VERSION ""

NS_ :

BS_:

BU_:

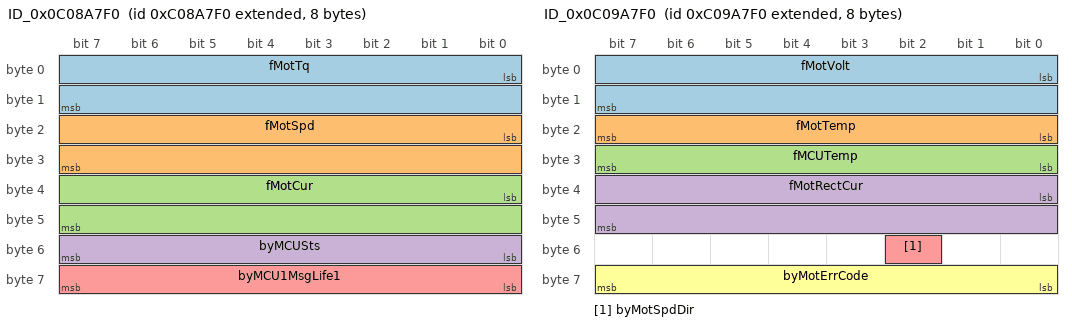
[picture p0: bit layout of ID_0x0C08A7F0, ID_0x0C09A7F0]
BO_ 2349377520 ID_0x0C08A7F0: 8 Vector__XXX
 SG_ fMotTq : 0|16@1+ (1,-32000) [-32000|33535] "NM" Vector__XXX
 SG_ fMotSpd : 16|16@1+ (0.5,0) [0|32767.5] "RPM" Vector__XXX
 SG_ fMotCur : 32|16@1+ (0.1,-1000) [-1000|5553.5] "A" Vector__XXX
 SG_ byMCUSts : 48|8@1+ (1,0) [0|255] "" Vector__XXX
 SG_ byMCU1MsgLife1 : 56|8@1+ (1,0) [0|255] "" Vector__XXX

BO_ 2349443056 ID_0x0C09A7F0: 8 Vector__XXX
 SG_ fMotVolt : 0|16@1+ (0.1,-1000) [-1000|5553.5] "V" Vector__XXX
 SG_ fMotTemp : 16|8@1+ (1,-40) [-40|215] "" Vector__XXX
 SG_ fMCUTemp : 24|8@1+ (1,-40) [-40|215] "" Vector__XXX
 SG_ fMotRectCur : 32|16@1+ (0.1,-1000) [-1000|5553.5] "A" Vector__XXX
 SG_ byMotSpdDir : 50|1@1+ (1,0) [0|1] "" Vector__XXX
 SG_ byMotErrCode : 56|8@1+ (1,0) [0|255] "" Vector__XXX

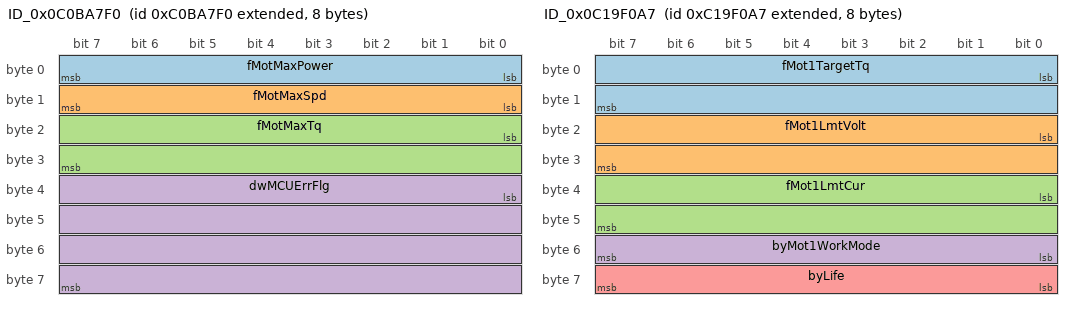
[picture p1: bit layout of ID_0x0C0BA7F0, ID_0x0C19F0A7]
BO_ 2349574128 ID_0x0C0BA7F0: 8 Vector__XXX
 SG_ fMotMaxPower : 0|8@1+ (1,0) [0|255] "kw" Vector__XXX
 SG_ fMotMaxSpd : 8|8@1+ (100,0) [0|25500] "rpm" Vector__XXX
 SG_ fMotMaxTq : 16|16@1+ (1,0) [0|65535] "NM" Vector__XXX
 SG_ dwMCUErrFlg : 32|32@1+ (1,0) [0|4294967295] "" Vector__XXX

BO_ 2350510247 ID_0x0C19F0A7: 8 Vector__XX
 SG_ fMot1TargetTq : 0|16@1+ (1,-32000) [-32000|33535] "NM" Vector__XXX
 SG_ fMot1LmtVolt : 16|16@1+ (0.1,-1000) [-1000|5553.5] "V" Vector__XXX
 SG_ fMot1LmtCur : 32|16@1+ (0.1,-1000) [-1000|5553.5] "A" Vector__XXX
 SG_ byMot1WorkMode : 48|8@1+ (1,0) [0|255] "" Vector__XXX
 SG_ byLife : 56|8@1+ (1,0) [0|255] "" Vector__XXX

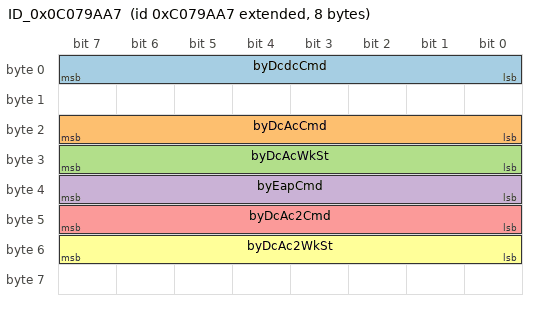
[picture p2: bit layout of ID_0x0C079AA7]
BO_ 2349308583 ID_0x0C079AA7: 8 Vector__XX
 SG_ byDcdcCmd : 0|8@1+ (1,0) [0|255] "" Vector__XXX
 SG_ byDcAcCmd : 16|8@1+ (1,0) [0|255] "" Vector__XXX
 SG_ byDcAcWkSt : 24|8@1+ (1,0) [0|255] "" Vector__XXX
 SG_ byEapCmd : 32|8@1+ (1,0) [0|255] "" Vector__XXX
 SG_ byDcAc2Cmd : 40|8@1+ (1,0) [0|255] "" Vector__XXX
 SG_ byDcAc2WkSt : 48|8@1+ (1,0) [0|255] "" Vector__XXX
